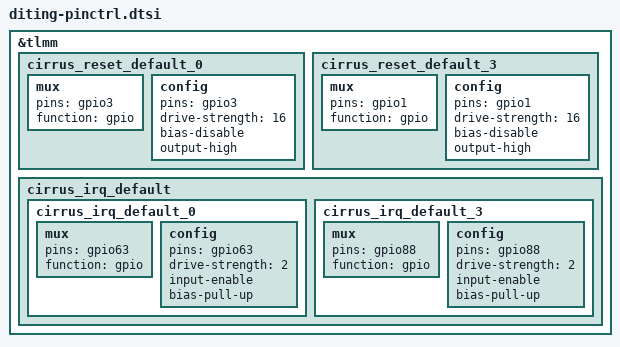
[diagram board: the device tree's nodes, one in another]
/*for unicorn pinctrl */

&tlmm {
	cirrus_reset_default_0: cirrus_reset_default_0 {
		mux {
			pins = "gpio3";
			function = "gpio";
		};

		config {
			pins = "gpio3";
			drive-strength = <16>;   /* 16 mA */
			bias-disable;
			output-high;
		};
	};

	cirrus_reset_default_3: cirrus_reset_default_3 {
		mux {
			pins = "gpio1";
			function = "gpio";
		};

		config {
			pins = "gpio1";
			drive-strength = <16>;   /* 16 mA */
			bias-disable;
			output-high;
		};
	};

	cirrus_irq_default {
		cirrus_irq_default_0: cirrus_irq_default_0 {
			mux {
				pins = "gpio63";
				function = "gpio";
			};
			config {
				pins = "gpio63";
				drive-strength = <2>;
				input-enable;
				bias-pull-up;
			};
		};
		cirrus_irq_default_3: cirrus_irq_default_3 {
			mux {
				pins = "gpio88";
				function = "gpio";
			};
			config {
				pins = "gpio88";
				drive-strength = <2>;
				input-enable;
				bias-pull-up;
			};
		};
	};
};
